# BlueNRG_LPF register map
File version: 1.0
CPU: CM0+ r0p0, little endian, no MPU, no FPU, 2 interrupt priority bits
Registers are 32-bit, read-write, reset 0x0 unless marked. A register's access mark holds for its fields unless they carry their own. Offsets are from the block's base; [hi:lo] are bit positions; {n}, {i} and the like mark numbered series; 'fields as' and 'values as' point back to an identical list.

## CRC — Cyclic redundancy check calculation unit
Base 0x48200000
0x00 DR reset 0xFFFFFFFF — Data register
  [31:0] DR — Data register bits
0x04 IDR — Independent data register
  [31:0] IDR — General-purpose 32-bit data register bits
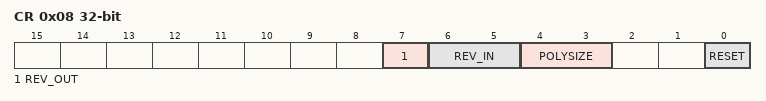
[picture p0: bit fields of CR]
0x08 CR — Control register
  [7] REV_OUT — Reverse output data
  [6:5] REV_IN — Reverse input data
  [4:3] POLYSIZE — Polynomial size
  [0] RESET wo — RESET bit
0x10 INIT reset 0xFFFFFFFF — Initial CRC value
  [31:0] INIT — Programmable initial CRC value
0x14 POL reset 0x4C11DB7 — polynomial
  [31:0] POL — Programmable polynomial

## DMA — Direct memory access controller
Base 0x48700000
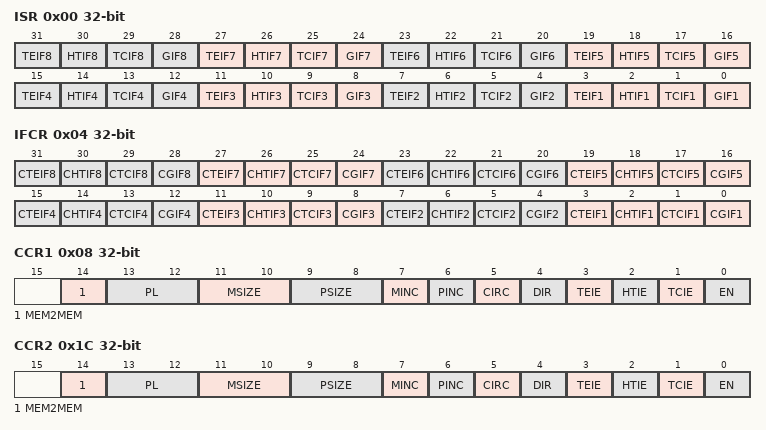
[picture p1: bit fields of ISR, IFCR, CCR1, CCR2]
0x00 ISR ro — interrupt status register
  [4n-1] TEIF{n} (n=1..8) — Channel {n} transfer error flag
  [4n-2] HTIF{n} (n=1..8) — Channel {n} half transfer flag
  [4n-3] TCIF{n} (n=1..8) — Channel {n} transfer complete flag
  [4n-4] GIF{n} (n=1..8) — Channel {n} global interrupt flag
0x04 IFCR wo — interrupt flag clear register
  [4n-1] CTEIF{n} (n=1..8) — Channel {n} transfer error clear
  [4n-2] CHTIF{n} (n=1..8) — Channel {n} half transfer clear
  [4n-3] CTCIF{n} (n=1..8) — Channel {n} transfer complete clear
  [4n-4] CGIF{n} (n=1..8) — Channel {n} global interrupt clear
0x08 CCR1 — channel 1 configuration register
  [14] MEM2MEM — Memory to memory mode
  [13:12] PL — Channel priority level
  [11:10] MSIZE — Memory size
  [9:8] PSIZE — Peripheral size
  [7] MINC — Memory increment mode
  [6] PINC — Peripheral increment mode
  [5] CIRC — Circular mode
  [4] DIR — Data transfer direction
  [3] TEIE — Transfer error interrupt enable
  [2] HTIE — Half transfer interrupt enable
  [1] TCIE — Transfer complete interrupt enable
  [0] EN — Channel enable
0x0C CNDTR1 — channel 1 number of data register
  [15:0] NDT — Number of data to transfer
0x10 CPAR1 — channel 1 peripheral address register
  [31:0] PA — Peripheral address
0x14 CMAR1 — channel x memory address register
  [31:0] MA — Memory address
0x1C CCR2 — channel 2 configuration register
  fields as CCR1
0x20 CNDTR2 — channel 2 number of data register
  [15:0] NDT — Number of data to transfer
0x24 CPAR2 — channel 2 peripheral address register
  [31:0] PA — Peripheral address
{0x0+0x14*i} CMAR{i} (i=2..8) — channel {i} memory address register
  [31:0] MA — Memory address
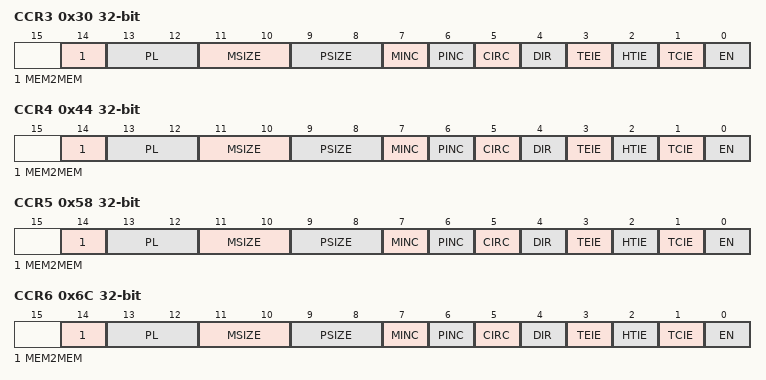
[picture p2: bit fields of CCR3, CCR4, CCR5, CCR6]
0x30 CCR3 — channel 3 configuration register
  fields as CCR1
0x34 CNDTR3 — channel 3 number of data register
  [15:0] NDT — Number of data to transfer
0x38 CPAR3 — channel 3 peripheral address register
  [31:0] PA — Peripheral address
0x44 CCR4 — channel 4 configuration register
  fields as CCR1
0x48 CNDTR4 — channel 4 number of data register
  [15:0] NDT — Number of data to transfer
0x4C CPAR4 — channel 4 peripheral address register
  [31:0] PA — Peripheral address
0x58 CCR5 — channel 5 configuration register
  fields as CCR1
0x5C CNDTR5 — channel 5 number of data register
  [15:0] NDT — Number of data to transfer
0x60 CPAR5 — channel 5 peripheral address register
  [31:0] PA — Peripheral address
0x6C CCR6 — channel 6 configuration register
  fields as CCR1
0x70 CNDTR6 — channel 6 number of data register
  [15:0] NDT — Number of data to transfer
0x74 CPAR6 — channel 6 peripheral address register
  [31:0] PA — Peripheral address
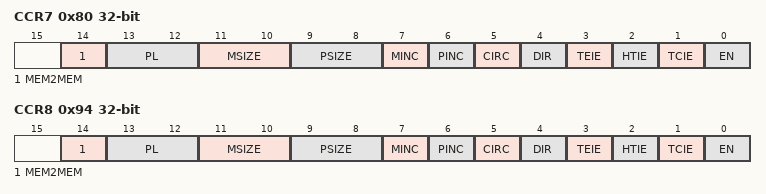
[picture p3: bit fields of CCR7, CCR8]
0x80 CCR7 — channel 7 configuration register
  fields as CCR1
0x84 CNDTR7 — channel 7 number of data register
  [15:0] NDT — Number of data to transfer
0x88 CPAR7 — channel 7 peripheral address register
  [31:0] PA — Peripheral address
0x94 CCR8 — channel 8 configuration register
  fields as CCR1
0x98 CNDTR8 — channel 8 number of data register
  [15:0] NDT — Number of data to transfer
0x9C CPAR8 — channel 8 peripheral address register
  [31:0] PA — Peripheral address
